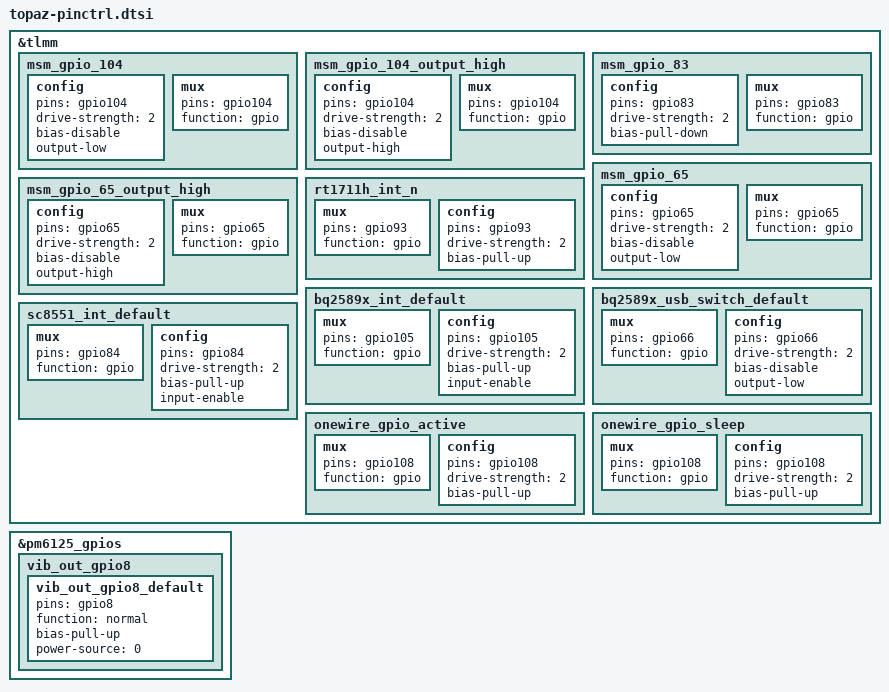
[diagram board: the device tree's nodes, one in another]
&tlmm {
	msm_gpio_104: msm_gpio_104 {
		config {
			pins = "gpio104";
			drive-strength = <2>;
			bias-disable;
			output-low;
		};

		mux {
			pins = "gpio104";
			function = "gpio";
		};
	};

	msm_gpio_104_output_high: msm_gpio_104_output_high {
		config {
			pins = "gpio104";
		    drive-strength = <2>;
			bias-disable;
			output-high;
		};

		mux {
			pins = "gpio104";
			function = "gpio";
		};
	};

	msm_gpio_83: msm_gpio_83 {
		config {
			pins = "gpio83";
			drive-strength = <2>;
			bias-pull-down;
		};

		mux {
			pins = "gpio83";
			function = "gpio";
		};

	};

	msm_gpio_65: msm_gpio_65 {
		config {
			pins = "gpio65";
			drive-strength = <2>;
			bias-disable;
			output-low;
		};

		mux {
			pins = "gpio65";
			function = "gpio";
		};
	};

	msm_gpio_65_output_high: msm_gpio_65_output_high {
		config {
			pins = "gpio65";
			drive-strength = <2>;
			bias-disable;
			output-high;
		};

		mux {
			pins = "gpio65";
			function = "gpio";
		};
	};

	/* GPIO_93 : CHG_PD_INT_N */
	rt1711h_int_n: rt1711h_int_n {
		mux {
			pins = "gpio93";
			function = "gpio";
		};
		config {
			pins = "gpio93";
			drive-strength = <2>;
			bias-pull-up;
		};
	};

	bq2589x_int_default: bq2589x_int_default {
		mux {
			pins = "gpio105";
			function = "gpio";
	    };

		config {
			pins = "gpio105";
			drive-strength = <2>;
			bias-pull-up;
			input-enable;
		};
	};

	bq2589x_usb_switch_default: bq2589x_usb_switch_default {
		mux {
			pins = "gpio66";
			function = "gpio";
		};

		config {
			pins = "gpio66";
			drive-strength = <2>;
			bias-disable;
			output-low;
		};
	};

	sc8551_int_default {
		mux {
			pins = "gpio84";
			function = "gpio";
		};

		config {
			pins = "gpio84";
			drive-strength = <2>;
			bias-pull-up;
			input-enable;
		};
	};

	onewire_gpio_active: onewire_gpio_active {
		mux {
			pins = "gpio108";
			function = "gpio";
		};

		config {
			pins = "gpio108";
			drive-strength = <2>;
			bias-pull-up;
		};
	};

	onewire_gpio_sleep: onewire_gpio_sleep {
		mux {
			pins = "gpio108";
			function = "gpio";
		};

		config {
			pins = "gpio108";
			drive-strength = <2>;
			bias-pull-up;
		};
	};
};

&pm6125_gpios {
	vib_out_gpio8 {
		vib_out_gpio8_default: vib_out_gpio8_default {
			pins = "gpio8";
			function = "normal";
			bias-pull-up;
			power-source = <0>; // 1.8V
		};
	};
};
